# CC3220SF register map
Vendor: Texas Instruments; Series: Wireless Connectivity MCU; File version: 1
SimpleLink(TM) CC3220SF wireless MCU
CPU: CM4 r1p0, little endian, no MPU, no FPU, 8 interrupt priority bits
Registers are 32-bit, read-write, reset 0x0 unless marked. A register's access mark holds for its fields unless they carry their own. Offsets are from the block's base; lines under a group give offsets from that group; [hi:lo] are bit positions; {n}, {i} and the like mark numbered series; 'fields as' and 'values as' point back to an identical list; <NAME> marks a mode.

## Memory map
0x00000000 _INTERRUPTS
0x40000000 WDT size 0x4
0x40004000 GPIOA0 size 0x4
0x40005000 GPIOA1 size 0x4
0x40006000 GPIOA2 size 0x4
0x40007000 GPIOA3 size 0x4
0x4000C000 UARTA0 size 0x4
0x4000D000 UARTA1 size 0x4
0x40020000 I2CA0 size 0x4
0x40024000 GPIOA4 size 0x4
0x40030000 TIMERA0 size 0x4
0x40031000 TIMERA1 size 0x4
0x40032000 TIMERA2 size 0x4
0x40033000 TIMERA3 size 0x4
0x400F5000 STACKDIE_CTRL size 0x4
0x400F7000 COMMON_REG size 0x4
0x400FD000 FLASH_CONTROL size 0x4
0x400FE000 SYSTEM_CONTROL size 0x4
0x400FF000 UDMA size 0x4
0x44018000 CAMERA size 0x4
0x4401C000 I2S size 0x4
0x44020000 SSPI size 0x4
0x44021000 GSPI size 0x4
0x44025000 ARCM size 0x4
0x44026000 APPS_CONFIG size 0x4
0x4402D000 GPRCM size 0x4
0x4402E000 OCP_SHARED size 0x4
0x4402E800 ADC size 0x4
0x4402F000 HIB1P2 size 0x4
0x4402F800 HIB3P3 size 0x4
0x44030000 DTHE size 0x4
0x44035000 SHAMD5 size 0x4
0x44037000 AES size 0x4
0x44039000 DES size 0x4
0xE000E000 NVIC size 0x4

## Interrupts
16 INTERRUPT_GPIOA0 (_INTERRUPTS) — GPIO port S0
17 INTERRUPT_GPIOA1 (_INTERRUPTS) — GPIO port S1
18 INTERRUPT_GPIOA2 (_INTERRUPTS) — GPIO port S2
19 INTERRUPT_GPIOA3 (_INTERRUPTS) — GPIO port S3
21 INTERRUPT_UART0 (_INTERRUPTS) — UART0 Rx and Tx
22 INTERRUPT_UART1 (_INTERRUPTS) — UART1 Rx and Tx
24 INTERRUPT_I2C (_INTERRUPTS) — I2C controller
30 INTERRUPT_ADC0 (_INTERRUPTS) — ADC Channel 0
31 INTERRUPT_ADC1 (_INTERRUPTS) — ADC Channel 1
32 INTERRUPT_ADC2 (_INTERRUPTS) — ADC Channel 2
33 INTERRUPT_ADC3 (_INTERRUPTS) — ADC Channel 3
34 INTERRUPT_WDT (_INTERRUPTS) — Watchdog Timer
35 INTERRUPT_TIMERA0A (_INTERRUPTS) — 16/32-Bit General Purpose Timer A0A
36 INTERRUPT_TIMERA0B (_INTERRUPTS) — 16/32-Bit General Purpose Timer A0B
37 INTERRUPT_TIMERA1A (_INTERRUPTS) — 16/32-Bit General Purpose Timer A1A
38 INTERRUPT_TIMERA1B (_INTERRUPTS) — 16/32-Bit General Purpose Timer A1B
39 INTERRUPT_TIMERA2A (_INTERRUPTS) — 16/32-Bit General Purpose Timer A2A
40 INTERRUPT_TIMERA2B (_INTERRUPTS) — 16/32-Bit General Purpose Timer A2B
51 INTERRUPT_TIMERA3A (_INTERRUPTS) — 16/32-Bit General Purpose Timer A3A
52 INTERRUPT_TIMERA3B (_INTERRUPTS) — 16/32-Bit General Purpose Timer A3B
62 INTERRUPT_UDMA (_INTERRUPTS) — uDMA Software Interrupt
177 INTERRUPT_I2S (_INTERRUPTS) — I2S controller
179 INTERRUPT_CAM (_INTERRUPTS) — Camera
184 INTERRUPT_RAMWR (_INTERRUPTS) — RAM WR Error
187 INTERRUPT_NET (_INTERRUPTS) — Network Interrupt
192 INTERRUPT_SPI (_INTERRUPTS) — SPI Interrupt

## WDT
Base 0x40000000
0x00 LOAD
0x04 VALUE
0x08 CTL
0x0C ICR
0x10 RIS
0x14 MIS
0x418 TEST
  [11:10] STALL_EN — Watchdog stall enable
0xC00 LOCK

## UARTA0
Base 0x4000C000
Same registers: UARTA1 0x4000D000
0x00 DR
  [7:0] DATA — Data Transmitted or Received
0x04 RSR_ECR
  [7:0] UART_ECR_DATA — Error Clear
0x18 FR
0x20 ILPR
  [7:0] ILPDVSR — IrDA Low-Power Divisor
0x24 IBRD
  [15:0] DIVINT — Integer Baud-Rate Divisor
0x28 FBRD
  [5:0] DIVFRAC — Fractional Baud-Rate Divisor
0x2C LCRH
  [6:5] WLEN — UART Word Length 0x00000000 : UART_LCRH_WLEN_5 : 5 bits (default) 0x00000020 : UART_LCRH_WLEN_6 : 6 bits 0x00000040 : UART_LCRH_WLEN_7 : 7 bits 0x00000060 : UART_LCRH_WLEN_8 : 8 bits
0x30 CTL
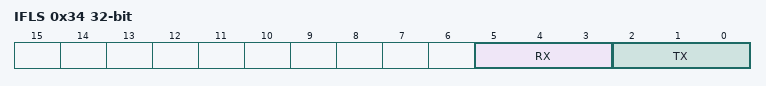
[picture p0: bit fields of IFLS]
0x34 IFLS
  [5:3] RX — UART Receive Interrupt FIFO Level Select
  [2:0] TX — UART Transmit Interrupt FIFO Level Select
0x38 IM
0x3C RIS
0x40 MIS
0x44 ICR
0x48 DMACTL
0x90 LCTL
  [5:4] BLEN — Sync Break Length 0x00000000 : UART_LCTL_BLEN_13T : Sync break length is 13T bits (default) 0x00000010 : UART_LCTL_BLEN_14T : Sync break length is 14T bits 0x00000020 : UART_LCTL_BLEN_15T : Sync break length is 15T bits 0x00000030 : UART_LCTL_BLEN_16T : Sync break length is 16T bits
0x94 LSS
  [15:0] TSS — Timer Snap Shot
0x98 LTIM
  [15:0] TIMER — Timer Value
0xA4 UART_9BITADDR
0xA8 UART_9BITAMASK
0xFC0 PP
0xFC8 CC
  [3:0] CS — UART Baud Clock Source 0x00000005 : UART_CC_CS_PIOSC : PIOSC 0x00000000 : UART_CC_CS_SYSCLK : The system clock (default)
